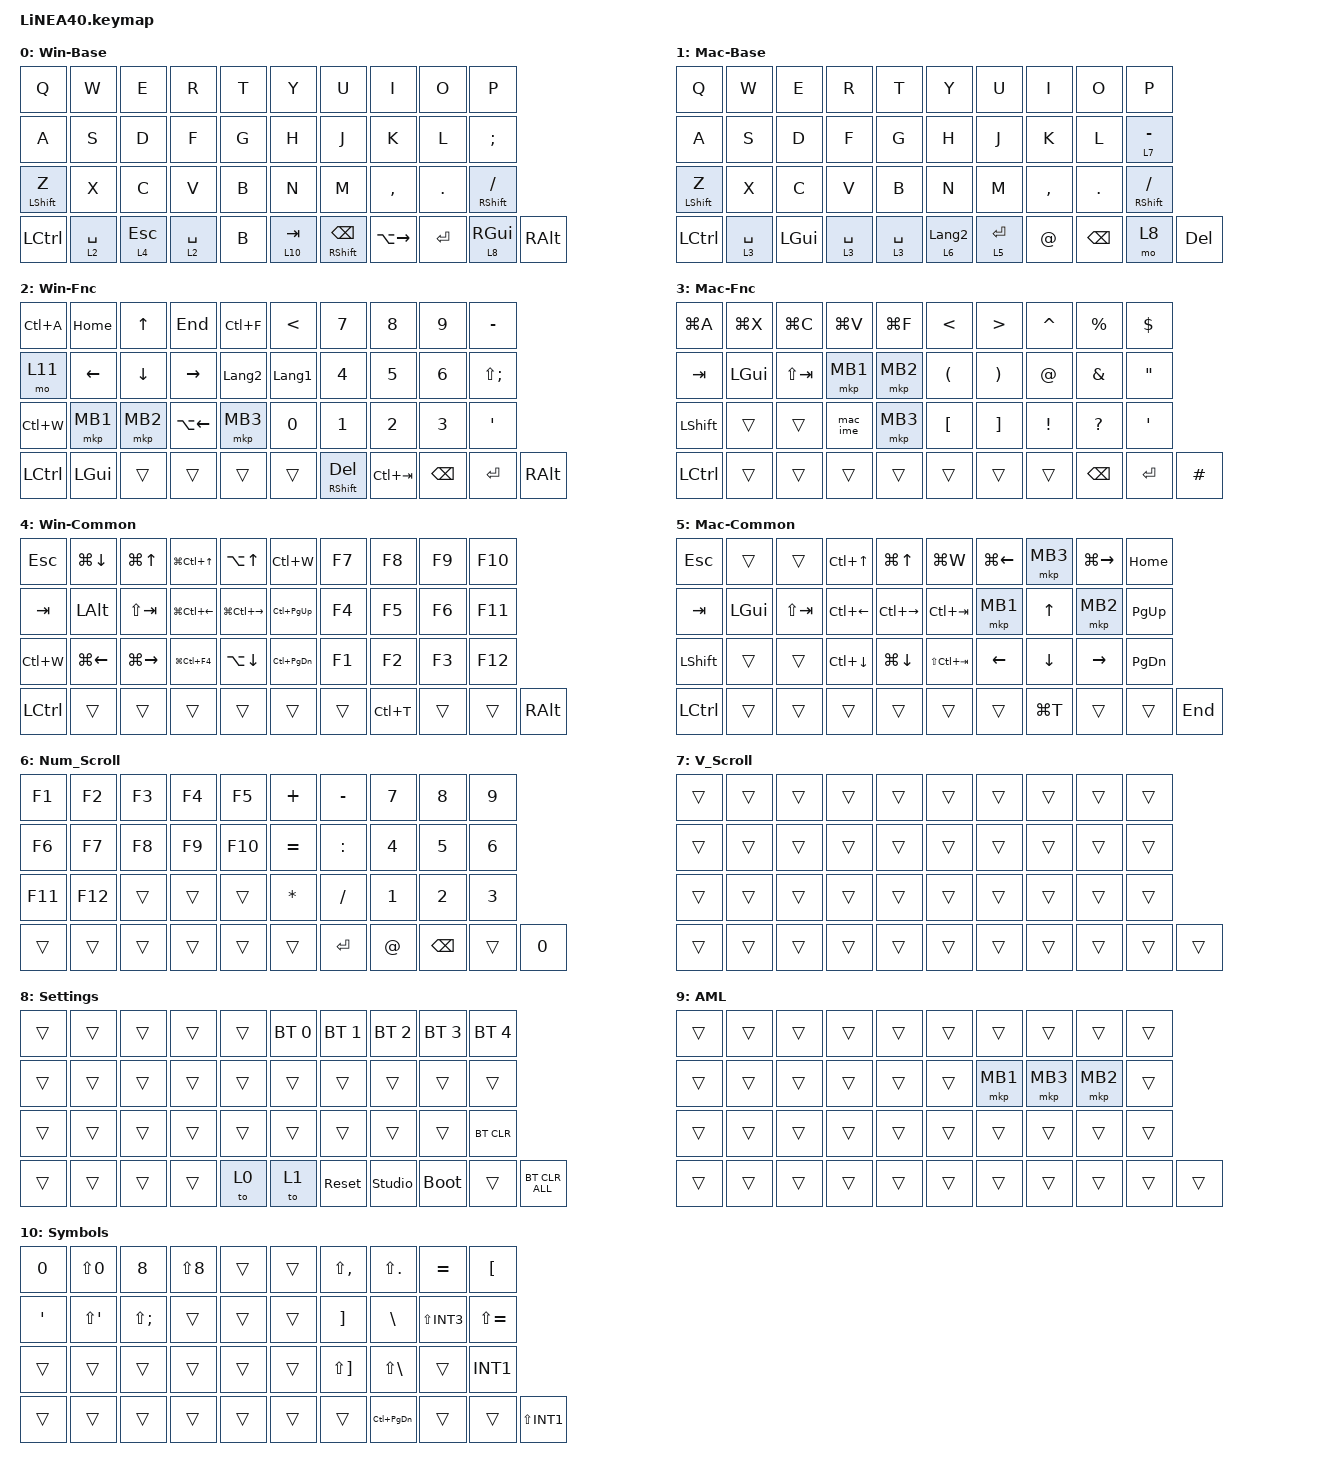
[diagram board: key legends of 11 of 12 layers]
// LiNEA40 port of ArroundForty keymap; 41 bindings per layer (including layout placeholder).
// Position 31 (zero-based): Space tap / Win-Fnc or Mac-Fnc hold; verify physical location against shield mapping.
// Build verification required after this revision; physical key positions and Studio behavior need testing.
// Keep LiNEA40 trackball/encoder definitions, preserve ArroundForty layers 0..10.
#define ZMK_POINTING_DEFAULT_SCRL_VAL 150
#include <dt-bindings/zmk/input_transform.h>
#include <input/processors.dtsi>
#include <zephyr/dt-bindings/input/input-event-codes.h>
#include <behaviors.dtsi>
#include <dt-bindings/zmk/bt.h>
#include <dt-bindings/zmk/keys.h>
#include <dt-bindings/zmk/pointing.h>

&mmv {
    delay-ms = <20>;
    trigger-period-ms = <5>;
    time-to-max-speed-ms = <100>;
    acceleration-exponent = <2>;
};
&msc {
    delay-ms = <3>;
    trigger-period-ms = <3>;
    time-to-max-speed-ms = <100>;
    acceleration-exponent = <0>;
};
/ {
    input_processors {
        zip_wheel_scaler: zip_wheel_scaler {
            compatible = "zmk,input-processor-scaler";
            #input-processor-cells = <2>;
            type = <INPUT_EV_REL>;
            codes = <INPUT_REL_WHEEL>;
            track-remainders;
        };
    };
};
// ArroundForty layers 4/5 = Win-Common / Mac-Common.
&msc_input_listener {
    speed_up {
        layers = <4 5>;
        input-processors = <&zip_wheel_scaler 3 1>;
    };
};
// ArroundForty layer 7 = V_Scroll.
&trackball_listener {
    scroller {
        layers = <7>;
        input-processors =
            <&zip_xy_transform INPUT_TRANSFORM_Y_INVERT>,
            <&zip_xy_to_scroll_mapper>,
            <&zip_wheel_scaler 3 8>;
    };
};
&lt {
    tapping-term-ms = <180>;
    flavor = "hold-preferred";
    
};

&mt {
    flavor = "balanced";
    quick-tap-ms = <0>;
};

/ {
    combos {
        compatible = "zmk,combos";

        Escape {
            bindings = <&kp ESCAPE>;
            key-positions = <0 1>;
        };
        // LiNEA40 factory combo positions; verify on physical device.
        ZenkakuHankaku { bindings = <&kp GRAVE>; key-positions = <11 12>; };
        DeleteKey { bindings = <&kp DEL>; key-positions = <7 8>; };
        InsertKey { bindings = <&kp INS>; key-positions = <6 7>; };
        CenterClick { bindings = <&mkp MB3>; key-positions = <17 16>; };
        RightClick { bindings = <&mkp MB2>; key-positions = <18 17>; };
        PrevClick { bindings = <&mkp MB4>; key-positions = <27 28>; };
        ClickNext { bindings = <&mkp MB5>; key-positions = <26 27>; };

    };

    macros {
        to_layer_0: to_layer_0 {
            compatible = "zmk,behavior-macro-one-param";
            #binding-cells = <1>;
            bindings = <&to 0 &macro_param_1to1 &kp MACRO_PLACEHOLDER>;
            label = "TO_LAYER_0";
        };

        // Windows用入力切り替え：Alt + Grave (~)

        ime_tog: ime_toggle {
            compatible = "zmk,behavior-macro";
            #binding-cells = <0>;
            bindings =
                <&macro_press>,
                <&kp LALT>,
                <&macro_tap>,
                <&kp GRAVE>,
                <&macro_release>,
                <&kp LALT>;
        };

        // macOS用入力切り替え：Ctrl + Space

        mac_ime: mac_ime_toggle {
            compatible = "zmk,behavior-macro";
            #binding-cells = <0>;
            bindings =
                <&macro_press>,
                <&kp LCTRL>,
                <&macro_tap>,
                <&kp SPACE>,
                <&macro_release>,
                <&kp LCTRL>;
        };

move_up_5: move_up_5 {
    compatible = "zmk,behavior-macro";
    #binding-cells = <0>;
    wait-ms = <40>;
    tap-ms = <40>;
    bindings = <
        &kp UP_ARROW &kp UP_ARROW &kp UP_ARROW
        &kp UP_ARROW &kp UP_ARROW
    >;
};

move_down_5: move_down_5 {
    compatible = "zmk,behavior-macro";
    #binding-cells = <0>;
    wait-ms = <40>;
    tap-ms = <40>;
    bindings = <
        &kp DOWN_ARROW &kp DOWN_ARROW &kp DOWN_ARROW
        &kp DOWN_ARROW &kp DOWN_ARROW
    >;
};

move_left_5: move_left_5 {
    compatible = "zmk,behavior-macro";
    #binding-cells = <0>;
    wait-ms = <40>;
    tap-ms = <40>;
    bindings = <
        &kp LEFT_ARROW &kp LEFT_ARROW &kp LEFT_ARROW
        &kp LEFT_ARROW &kp LEFT_ARROW
    >;
};

move_right_5: move_right_5 {
    compatible = "zmk,behavior-macro";
    #binding-cells = <0>;
    wait-ms = <40>;
    tap-ms = <40>;
    bindings = <
        &kp RIGHT_ARROW &kp RIGHT_ARROW &kp RIGHT_ARROW
        &kp RIGHT_ARROW &kp RIGHT_ARROW
    >;
};

    };

    behaviors {
        lt_to_layer_0: lt_to_layer_0 {
            compatible = "zmk,behavior-hold-tap";
            label = "LAYER_TAP_TO_0";
            bindings = <&mo>, <&to_layer_0>;

            #binding-cells = <2>;
            tapping-term-ms = <200>;
        };

        // 

        re_kp: sensor_rotate_kp {
            compatible = "zmk,behavior-sensor-rotate-var";
            #sensor-binding-cells = <2>;
            bindings = <&kp>, <&kp>;
        };
        mouse_scrl: mouse_wheel_scrl {
            compatible = "zmk,behavior-sensor-rotate-var";
            #sensor-binding-cells = <2>;
            bindings = <&msc>, <&msc>;
            tap-ms = <20>;
        };
        scroll_up_down: behavior_sensor_rotate_mouse_wheel_up_down {
            compatible = "zmk,behavior-sensor-rotate";
            #sensor-binding-cells = <0>;
            bindings = <&msc SCRL_UP>, <&msc SCRL_DOWN>;

            tap-ms = <20>;
        };
    };

    keymap {
        compatible = "zmk,keymap";

        // Layer 0: Win-Base
        Win_Base {
            display-name = "Win-Base";
            bindings = <
                &kp Q  &kp W  &kp E  &kp R  &kp T  &kp Y  &kp U  &kp I  &kp O  &kp P
                &kp A  &kp S  &kp D  &kp F  &kp G  &kp H  &kp J  &kp K  &kp L  &kp SEMI
                &mt LEFT_SHIFT Z  &kp X  &kp C  &kp V  &kp B  &kp N  &kp M  &kp COMMA  &kp DOT  &mt RIGHT_SHIFT SLASH
                &kp LCTRL  &lt 2 SPACE  &lt 4 ESC  &lt 2 SPACE  &kp B  &lt 10 TAB  &mt RIGHT_SHIFT BACKSPACE  &kp LA(RIGHT)  &kp ENTER  &lt 8 RIGHT_GUI  &kp RIGHT_ALT
            >;
            sensor-bindings = <&mouse_scrl SCRL_DOWN SCRL_UP>;
        };

        // Layer 1: Mac-Base
        Mac_Base {
            display-name = "Mac-Base";
            bindings = <
                &kp Q  &kp W  &kp E  &kp R  &kp T  &kp Y  &kp U  &kp I  &kp O  &kp P
                &kp A  &kp S  &kp D  &kp F  &kp G  &kp H  &kp J  &kp K  &kp L  &lt 7 MINUS
                &mt LEFT_SHIFT Z  &kp X  &kp C  &kp V  &kp B  &kp N  &kp M  &kp COMMA  &kp DOT  &mt RIGHT_SHIFT SLASH
                &kp LCTRL  &lt 3 SPACE  &kp LEFT_GUI  &lt 3 SPACE  &lt 3 SPACE  &lt 6 LANGUAGE_2  &lt 5 ENTER  &kp AT_SIGN  &kp BACKSPACE  &mo 8  &kp DEL
            >;
            sensor-bindings = <&mouse_scrl SCRL_DOWN SCRL_UP>;
        };

        // Layer 2: Win-Fnc
        Win_Fnc {
            display-name = "Win-Fnc";
            bindings = <
                &kp LC(A)  &kp HOME  &kp UP_ARROW  &kp END  &kp LC(F)  &kp LESS_THAN  &kp N7  &kp N8  &kp N9  &kp MINUS
                &mo 11  &kp LEFT_ARROW  &kp DOWN_ARROW  &kp RIGHT_ARROW  &kp LANGUAGE_2  &kp LANGUAGE_1  &kp N4  &kp N5  &kp N6  &kp LS(SEMI)
                &kp LC(W)  &mkp MB1  &mkp MB2  &kp LA(LEFT)  &mkp MB3  &kp N0  &kp N1  &kp N2  &kp N3  &kp SINGLE_QUOTE
                &kp LCTRL  &kp LGUI  &trans  &trans  &trans  &trans  &mt RIGHT_SHIFT DELETE  &kp LC(TAB)  &kp BACKSPACE  &kp ENTER  &kp RIGHT_ALT
            >;
        };

        // Layer 3: Mac-Fnc
        Mac_Fnc {
            display-name = "Mac-Fnc";
            bindings = <
                &kp LG(A)  &kp LG(X)  &kp LG(C)  &kp LG(V)  &kp LG(F)  &kp LESS_THAN  &kp GREATER_THAN  &kp CARET  &kp PERCENT  &kp DOLLAR
                &kp TAB  &kp LEFT_GUI  &kp LS(TAB)  &mkp MB1  &mkp MB2  &kp LEFT_PARENTHESIS  &kp RIGHT_PARENTHESIS  &kp AT_SIGN  &kp AMPERSAND  &kp DOUBLE_QUOTES
                &kp LEFT_SHIFT  &trans  &trans  &mac_ime  &mkp MB3  &kp LEFT_BRACKET  &kp RIGHT_BRACKET  &kp EXCLAMATION  &kp QUESTION  &kp SINGLE_QUOTE
                &kp LCTRL  &trans  &trans  &trans  &trans  &trans  &trans  &trans  &kp BACKSPACE  &kp ENTER  &kp HASH
            >;
        };

        // Layer 4: Win-Common
        Win_Common {
            display-name = "Win-Common";
            bindings = <
                &kp ESC  &kp LG(DOWN_ARROW)  &kp LG(UP_ARROW)  &kp LG(LC(UP_ARROW))  &kp LA(UP_ARROW)  &kp LC(W)  &kp F7  &kp F8  &kp F9  &kp F10
                &kp TAB  &kp LEFT_ALT  &kp LS(TAB)  &kp LG(LC(LEFT_ARROW))  &kp LG(LC(RIGHT_ARROW))  &kp LC(PAGE_UP)  &kp F4  &kp F5  &kp F6  &kp F11
                &kp LC(W)  &kp LG(LEFT_ARROW)  &kp LG(RIGHT_ARROW)  &kp LG(LC(F4))  &kp LA(DOWN_ARROW)  &kp LC(PAGE_DOWN)  &kp F1  &kp F2  &kp F3  &kp F12
                &kp LCTRL  &trans  &trans  &trans  &trans  &trans  &trans  &kp LC(T)  &trans  &trans  &kp RIGHT_ALT
            >;
            sensor-bindings = <&mouse_scrl SCRL_DOWN SCRL_UP>;
        };

        // Layer 5: Mac-Common
        Mac_Common {
            display-name = "Mac-Common";
            bindings = <
                &kp ESC  &trans  &trans  &kp LC(UP_ARROW)  &kp LG(UP_ARROW)  &kp LG(W)  &kp LG(LEFT_ARROW)  &mkp MB3  &kp LG(RIGHT_ARROW)  &kp HOME
                &kp TAB  &kp LEFT_GUI  &kp LS(TAB)  &kp LC(LEFT_ARROW)  &kp LC(RIGHT_ARROW)  &kp LC(TAB)  &mkp MB1  &kp UP_ARROW  &mkp MB2  &kp PAGE_UP
                &kp LSHFT  &trans  &trans  &kp LC(DOWN_ARROW)  &kp LG(DOWN_ARROW)  &kp LS(LC(TAB))  &kp LEFT_ARROW  &kp DOWN_ARROW  &kp RIGHT_ARROW  &kp PAGE_DOWN
                &kp LCTRL  &trans  &trans  &trans  &trans  &trans  &trans  &kp LG(T)  &trans  &trans  &kp END
            >;
            sensor-bindings = <&mouse_scrl SCRL_DOWN SCRL_UP>;
        };

        // Layer 6: Num_Scroll
        Num_Scroll {
            display-name = "Num_Scroll";
            bindings = <
                &kp F1  &kp F2  &kp F3  &kp F4  &kp F5  &kp PLUS  &kp MINUS  &kp N7  &kp N8  &kp N9
                &kp F6  &kp F7  &kp F8  &kp F9  &kp F10  &kp EQUAL  &kp COLON  &kp N4  &kp N5  &kp N6
                &kp F11  &kp F12  &trans  &trans  &trans  &kp ASTERISK  &kp FSLH  &kp N1  &kp N2  &kp N3
                &trans  &trans  &trans  &trans  &trans  &trans  &kp ENTER  &kp AT_SIGN  &kp BSPC  &trans  &kp N0
            >;
        };

        // Layer 7: V_Scroll
        V_Scroll {
            display-name = "V_Scroll";
            bindings = <
                &trans  &trans  &trans  &trans  &trans  &trans  &trans  &trans  &trans  &trans
                &trans  &trans  &trans  &trans  &trans  &trans  &trans  &trans  &trans  &trans
                &trans  &trans  &trans  &trans  &trans  &trans  &trans  &trans  &trans  &trans
                &trans  &trans  &trans  &trans  &trans  &trans  &trans  &trans  &trans  &trans  &trans
            >;
            sensor-bindings = <&mouse_scrl SCRL_RIGHT SCRL_LEFT>;
        };

        // Layer 8: Settings
        Settings {
            // Bottom row positions 34/35 (zero-based): switch to Win-Base / Mac-Base.
            display-name = "Settings";
            bindings = <
                &trans  &trans  &trans  &trans  &trans  &bt BT_SEL 0  &bt BT_SEL 1  &bt BT_SEL 2  &bt BT_SEL 3  &bt BT_SEL 4
                &trans  &trans  &trans  &trans  &trans  &trans  &trans  &trans  &trans  &trans
                &trans  &trans  &trans  &trans  &trans  &trans  &trans  &trans  &trans  &bt BT_CLR
                &trans  &trans  &trans  &trans  &to 0  &to 1  &sys_reset  &studio_unlock  &bootloader  &trans  &bt BT_CLR_ALL
            >;
        };

        // Layer 9: AML
        AML {
            display-name = "AML";
            bindings = <
                &trans  &trans  &trans  &trans  &trans  &trans  &trans  &trans  &trans  &trans
                &trans  &trans  &trans  &trans  &trans  &trans  &mkp MB1  &mkp MB3  &mkp MB2  &trans
                &trans  &trans  &trans  &trans  &trans  &trans  &trans  &trans  &trans  &trans
                &trans  &trans  &trans  &trans  &trans  &trans  &trans  &trans  &trans  &trans  &trans
            >;
        };

        // Layer 10: Symbols
        Symbols {
            display-name = "Symbols";
            bindings = <
                &kp N0  &kp LS(N0)  &kp N8  &kp LS(N8)  &trans  &trans  &kp LS(COMMA)  &kp LS(DOT)  &kp EQUAL  &kp LEFT_BRACKET
                &kp SINGLE_QUOTE  &kp LS(SINGLE_QUOTE)  &kp LS(SEMI)  &trans  &trans  &trans  &kp RIGHT_BRACKET  &kp BACKSLASH  &kp LS(INT3)  &kp LS(EQUAL)
                &trans  &trans  &trans  &trans  &trans  &trans  &kp LS(RIGHT_BRACKET)  &kp LS(BACKSLASH)  &trans  &kp INT1
                &trans  &trans  &trans  &trans  &trans  &trans  &trans  &kp LC(PAGE_DOWN)  &trans  &trans  &kp LS(INT1)
            >;
        };

        // Layer 11: Move5
Move5 {
    display-name = "Move5";
    bindings = <
        &trans &trans &move_up_5 &trans &trans
        &trans &trans &trans &trans &trans

        &trans &move_left_5 &move_down_5 &move_right_5 &trans
        &trans &trans &trans &trans &trans

        &trans &trans &trans &trans &trans
        &trans &trans &trans &trans &trans

        &trans &trans &trans &trans &trans &trans
        &trans &trans &trans &trans &trans &trans
    >;
};

    };
};
